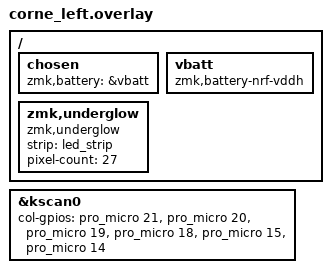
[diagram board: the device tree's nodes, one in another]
/*
 * Copyright (c) 2020 Pete Johanson
 *
 * SPDX-License-Identifier: MIT
 */

#include "corne.dtsi"

&kscan0 {
    col-gpios
		= <&pro_micro 21 GPIO_ACTIVE_HIGH>
		, <&pro_micro 20 GPIO_ACTIVE_HIGH>
		, <&pro_micro 19 GPIO_ACTIVE_HIGH>
		, <&pro_micro 18 GPIO_ACTIVE_HIGH>
		, <&pro_micro 15 GPIO_ACTIVE_HIGH>
		, <&pro_micro 14 GPIO_ACTIVE_HIGH>
		;
};
/ {
    chosen {
      zmk,battery = &vbatt;
    };

    vbatt: vbatt {
        compatible = "zmk,battery-nrf-vddh";
    };
};

/ {
    /* Tu led_strip ya definido… */

    zmk,underglow {
        compatible = "zmk,underglow";
        strip = <&led_strip>;        /* ¡Apunta a tu nodo real! */
        pixel-count = <27>;          /* 21 delante + 6 atrás = 27 por MITAD */
        /* opcional: effect = "breathing";  speed = <3>;  */
    };
};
